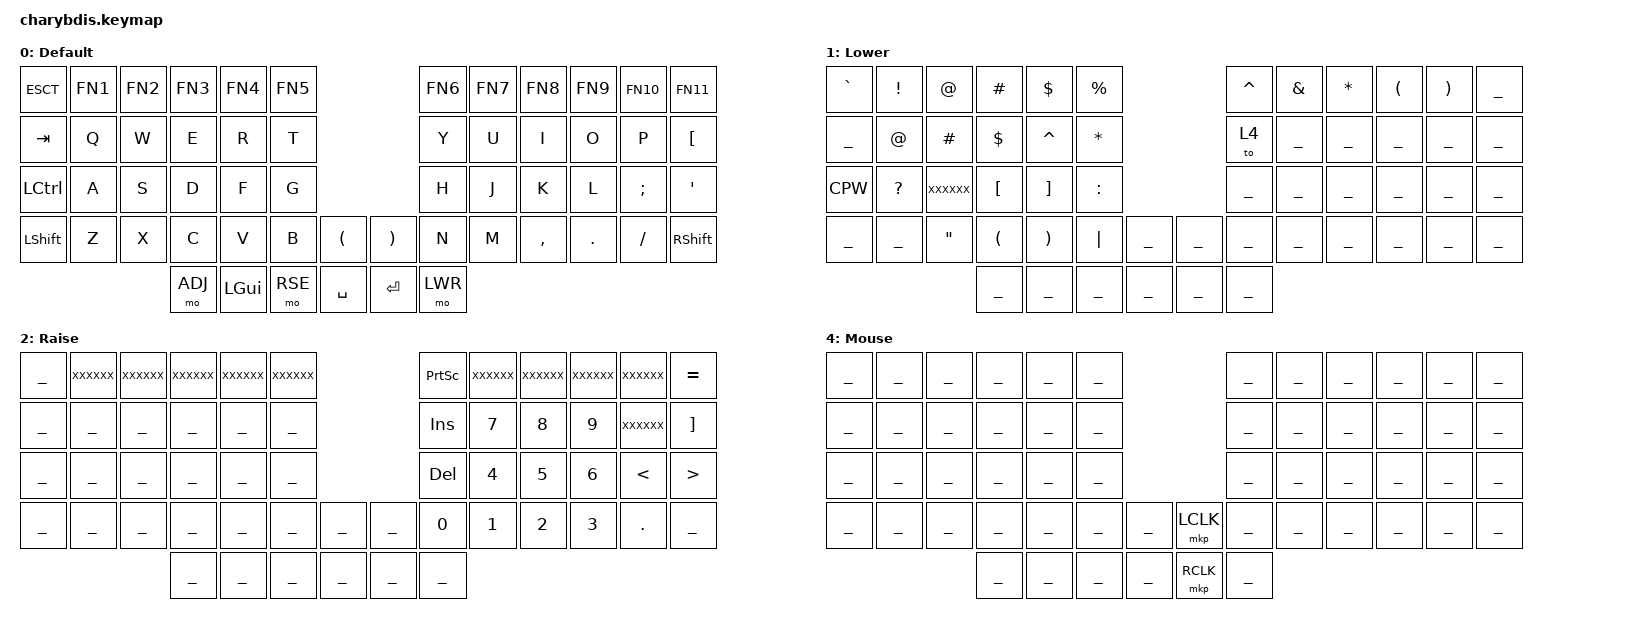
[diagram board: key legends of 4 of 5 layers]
/*
 * Copyright (c) 2020 The ZMK Contributors
 *
 * SPDX-License-Identifier: MIT
 */

#include <behaviors.dtsi>
#include <dt-bindings/zmk/keys.h>
#include <dt-bindings/zmk/bt.h>
#include <dt-bindings/zmk/outputs.h>
#include <dt-bindings/zmk/mouse.h>
#include "charybdis.h"

&kscan0 {
    debounce-press-ms = <3>;
    debounce-release-ms = <3>;
    debounce-scan-period-ms = <10>;
};

&mt {
    flavor = "tap-preferred";
    tapping-term-ms = <400>;
    quick-tap-ms = <200>;
};

&caps_word {
    continue-list = <UNDER MINUS BSPC>;
};

/ {
        keymap {
                compatible = "zmk,keymap";
				
				Default {
                	label = "Default";
                      bindings = <
    
                     ESCT     FN1      FN2      FN3      FN4      FN5                             FN6     FN7      FN8      FN9      FN10    FN11

                   &kp TAB   &kp Q    &kp W    &kp E    &kp R    &kp T                            &kp Y   &kp U    &kp I    &kp O    &kp P   &kp LBKT

                  &kp LCTRL  &kp A    &kp S    &kp D    &kp F    &kp G                            &kp H   &kp J    &kp K    &kp L   &kp SEMI &kp SQT

                  &kp LSHFT  &kp Z    &kp X    &kp C    &kp V    &kp B   &kp LPAR      &kp RPAR   &kp N   &kp M  &kp COMMA &kp DOT &kp SLASH &kp RSHFT

                                           &mo ADJ  &kp LGUI  &mo RSE    &kp SPACE     &kp ENTER  &mo LWR 
                       >;
                       trackball-bindings = <&tmv_coarse>;
                };

   				Lower {
                	label = "Lower";
                	bindings = <

                  &kp GRAVE &kp EXCL  &kp AT  &kp HASH &kp DLLR &kp PRCNT                        &kp CARET &kp AMPS &kp STAR &kp LPRN &kp RPRN &kp UNDER  

                    ______   &kp AT  &kp HASH &kp DLLR &kp CARET &kp STAR                        &to 4    ______   ______   ______   ______   ______

                     CPW   &kp QMARK  XXXXXX  &kp LBKT &kp RBKT &kp COLN                         ______   ______   ______   ______   ______   ______

                    ______ &kp UNDER &kp DQT  &kp LPRN &kp RPRN &kp PIPE  ______        ______   ______   ______   ______   ______   ______   ______

                                            ______   ______   ______      ______        ______   ______
                       >;
                       trackball-bindings = <&tmv_fine>; 
                };

				Raise {
            		label = "Raise";
              		bindings = <

                    ______   XXXXXX   XXXXXX   XXXXXX   XXXXXX   XXXXXX                          &kp PSCRN  XXXXXX   XXXXXX   XXXXXX   XXXXXX   &kp EQL

                    ______   ______   ______   ______   ______   ______                          &kp INS   &kp N7   &kp N8   &kp N9   XXXXXX  &kp RBKT

                    ______   ______   ______   ______   ______   ______                          &kp DEL  &kp N4   &kp N5   &kp N6   &kp LT   &kp GT

                    ______   ______   ______   ______   ______   ______   ______        ______   &kp N0   &kp N1   &kp N2   &kp N3   &kp DOT  ______

                                            ______   ______   ______      ______        ______   ______

                      >;
                      trackball-bindings = <&tsl_fine>;
                };
				
				Adjust {
            		label = "Adjust";
                    bindings = <

                    ______   Z_BT_0   Z_BT_1   Z_BT_2   Z_BT_3   Z_BT_4                          Z_VUP    XXXXXX   XXXXXX   XXXXXX   XXXXXX   XXXXXX

                    ______   ______   ______   ______   OUT_T    Z_BT_C                          Z_VDN   &kp HOME  &kp UP  &kp END  &kp PGUP &kp BSLH

                    ______   ______   ______   ______   ______   ______                          Z_MUT   &kp LEFT &kp DOWN &kp RIGHT &kp PGDN ______

                    ______   ______   ______   ______   ______   Z_BOOT   &vim_s        &vim_q   Z_BOOT   ______    ______   ______  &kp BSLH  ______

                                            ______   ______   ______    ______          ______   ______   

                      >;
                      trackball-bindings = <&tmv_fine>;
                };

				Mouse {
					label = "Mouse";
                    bindings = <

                    ______   ______   ______   ______   ______   ______                          ______   ______   ______   ______   ______   ______

                    ______   ______   ______   ______   ______   ______                          ______   ______   ______   ______   ______   ______

                    ______   ______   ______   ______   ______   ______                          ______   ______   ______   ______   ______   ______

                    ______   ______   ______   ______   ______   ______   ______       &mkp LCLK ______   ______   ______   ______   ______   ______

                                               ______   ______   ______   ______       &mkp RCLK ______   

                      >;
                      trackball-bindings = <&tmv_fine>;
                };
        };

    combos {
        compatible = "zmk,combos";
        //COMBO(nlock,  &tog RSE, 28 31)
        COMBO(caps,   &kp CAPS, 25 34)
    };
    
    macros {
        MACRO(vim_q,  &kp COLON &kp Q &kp EXCL)
        MACRO(vim_s,  &kp COLON &kp W &kp Q)
        MACRO(dir_up, &kp DOT &kp DOT &kp FSLH)
    };
};
